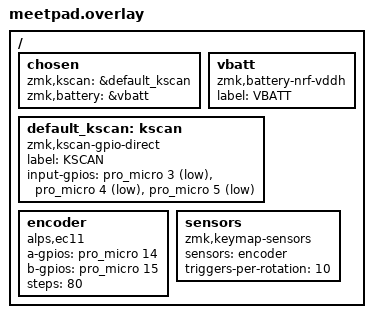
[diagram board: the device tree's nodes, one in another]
/ {
    chosen {
        zmk,kscan = &default_kscan;
        zmk,battery = &vbatt;
    };

    vbatt: vbatt {
            compatible = "zmk,battery-nrf-vddh";
            label = "VBATT";
    };

    default_kscan: kscan {
        compatible = "zmk,kscan-gpio-direct";
        label = "KSCAN";

        input-gpios =
            <&pro_micro 3 (GPIO_ACTIVE_LOW | GPIO_PULL_UP)>,
            <&pro_micro 4 (GPIO_ACTIVE_LOW | GPIO_PULL_UP)>,
            <&pro_micro 5 (GPIO_ACTIVE_LOW | GPIO_PULL_UP)>;
    };

    encoder: encoder {
        compatible = "alps,ec11";
        a-gpios = <&pro_micro 14 (GPIO_ACTIVE_HIGH | GPIO_PULL_UP)>;
        b-gpios = <&pro_micro 15 (GPIO_ACTIVE_HIGH | GPIO_PULL_UP)>;
        steps = <80>;
        status = "okay";
    };

    sensors: sensors {
        compatible = "zmk,keymap-sensors";
        sensors = <&encoder>;
        triggers-per-rotation = <10>;
    };
};
